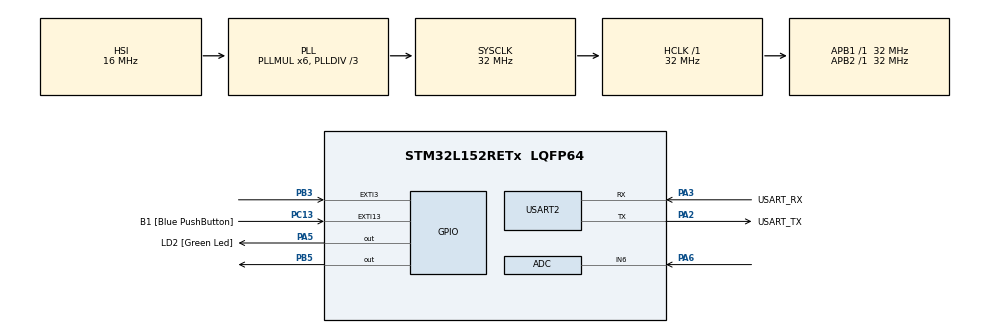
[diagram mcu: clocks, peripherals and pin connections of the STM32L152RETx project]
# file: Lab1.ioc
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ADC.Channel-0\#ChannelRegularConversion=ADC_CHANNEL_6
ADC.NbrOfConversionFlag=1
ADC.Rank-0\#ChannelRegularConversion=1
ADC.SamplingTime-0\#ChannelRegularConversion=ADC_SAMPLETIME_4CYCLES
Mcu.Family=STM32L1
Mcu.Name=STM32L152RETx
Mcu.Package=LQFP64
NVIC.PriorityGroup=NVIC_PRIORITYGROUP_0
PA13.GPIO_Label=TMS
PA13.Mode=Serial_Wire
PA13.Signal=SYS_JTMS-SWDIO
PA14.GPIO_Label=TCK
PA14.Mode=Serial_Wire
PA14.Signal=SYS_JTCK-SWCLK
PA2.GPIO_Label=USART_TX
PA2.Mode=Asynchronous
PA2.Signal=USART2_TX
PA3.GPIO_Label=USART_RX
PA3.Mode=Asynchronous
PA3.Signal=USART2_RX
PA5.GPIO_Label=LD2 [Green Led]
PA5.Signal=GPIO_Output
PA6.Mode=IN6
PA6.Signal=ADC_IN6
PB3.Signal=GPXTI3
PB5.Signal=GPIO_Output
PC13-WKUP2.GPIO_Label=B1 [Blue PushButton]
PC13-WKUP2.Signal=GPXTI13
PC14-OSC32_IN.Mode=LSE-External-Oscillator
PC14-OSC32_IN.Signal=RCC_OSC32_IN
PC15-OSC32_OUT.Mode=LSE-External-Oscillator
PC15-OSC32_OUT.Signal=RCC_OSC32_OUT
PH0-OSC_IN.Mode=HSE-External-Clock-Source
PH0-OSC_IN.Signal=RCC_OSC_IN
PH1-OSC_OUT.Signal=RCC_OSC_OUT
ProjectManager.HeapSize=0x200
ProjectManager.StackSize=0x400
ProjectManager.TargetToolchain=STM32CubeIDE
RCC.48MHZClocksFreq_Value=48000000
RCC.AHBFreq_Value=32000000
RCC.APB1Freq_Value=32000000
RCC.APB1TimFreq_Value=32000000
RCC.APB2Freq_Value=32000000
RCC.APB2TimFreq_Value=32000000
RCC.HCLKFreq_Value=32000000
RCC.HSE_VALUE=8000000
RCC.HSI_VALUE=16000000
RCC.MSI_VALUE=2097000
RCC.PLLDIV=RCC_PLL_DIV3
RCC.PLLMUL=RCC_PLL_MUL6
RCC.RTCClockSelectionVirtual=RCC_RTCCLKSOURCE_LSE
RCC.SYSCLKFreq_VALUE=32000000
RCC.SYSCLKSource=RCC_SYSCLKSOURCE_PLLCLK
RCC.USBOutput=48000000
RCC.VCOOutputFreq_Value=96000000
USART2.VirtualMode=VM_ASYNC
board=NUCLEO-L152RE

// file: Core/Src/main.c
/* USER CODE BEGIN Header */
/**
  ******************************************************************************
  * @file           : main.c
  * @brief          : Main program body
  ******************************************************************************
  * @attention
  *
  * Copyright (c) 2026 STMicroelectronics.
  * All rights reserved.
  *
  * This software is licensed under terms that can be found in the LICENSE file
  * in the root directory of this software component.
  * If no LICENSE file comes with this software, it is provided AS-IS.
  *
  ******************************************************************************
  */
/* USER CODE END Header */
#include "main.h"

/* USER CODE BEGIN Includes */
extern UART_HandleTypeDef huart2;

int _write(int file, char *ptr, int len) {
	int i=0;
	for(i=0; i<len; i++)
	HAL_UART_Transmit(&huart2,(uint8_t *)(ptr++),1,1000);
	return len;
}
void waiting(unsigned int delay) {
	unsigned int i;
	for (i=0; i<delay; i++);
}
/* USER CODE END Includes */

ADC_HandleTypeDef hadc;

UART_HandleTypeDef huart2;

/* USER CODE BEGIN PV */
unsigned char state = 0;
unsigned char medicion_init = 0;
unsigned char medicion_end = 1;
uint32_t value_adc = 0;
int angle = 0;
/* USER CODE END PV */

void SystemClock_Config(void);
static void MX_GPIO_Init(void);
static void MX_ADC_Init(void);
static void MX_USART2_UART_Init(void);

/* USER CODE BEGIN 0 */
void EXTI15_10_IRQHandler(void){
	if(EXTI->PR & (1 << 13)){
		EXTI->PR = (0x01 << 13);
		state = state + 1;
		if (state >1) state = 0;
		if (medicion_end == 0) printf("El cambio se realizara al terminar la medicion \r\n");
	}
}

void EXTI4_IRQHandler(void){
	// no need to verify EXTI PR as it only triggers this function with EXTI4
	EXTI->PR = (0x01 << 4);
	medicion_init = 1;
	medicion_end = 0;

}
/* USER CODE END 0 */

int main(void)
{

  /* USER CODE BEGIN 1 */
	unsigned char prev_state = 0;
  /* USER CODE END 1 */

  /* MCU Configuration--------------------------------------------------------*/

  /* Reset of all peripherals, Initializes the Flash interface and the Systick. */
  HAL_Init();

  /* Configure the system clock */
  SystemClock_Config();

  /* Initialize all configured peripherals */
  MX_GPIO_Init();
  MX_ADC_Init();
  MX_USART2_UART_Init();
  /* USER CODE BEGIN 2 */
  /*INPUTS: */
  /*PB4 configuration EXTI mode, moder (00)*/
  GPIOB ->MODER &= ~(1 << (4*2 + 1));
  GPIOB ->MODER &= ~(1 << (4*2));
  GPIOB ->PUPDR &= ~(3 << 8); // cleaning any previous configuration
  GPIOB ->PUPDR |= (2 << 8); // Setting button on pull down (10)

  SYSCFG ->EXTICR[1] &= ~(0xF << 0);	//Cleaning any new previous at SYSCFG
  SYSCFG->EXTICR[1] |= (0x01 << 0);		// Enabling EXTI4 for PB4 with 0001
  EXTI ->FTSR &= ~(0x01 << 4);			// Disabling falling edge
  EXTI ->RTSR |= (0x01 << 4);			// Enabling rising edge
  EXTI ->IMR |= (0x01 << 4); 			// Enable EXTI 4
  NVIC ->ISER[0] |= (1 << 10); 	// Enable EXTI4 NVIC

  /*PC13 configuration EXTI mode, moder(00)*/
  GPIOC ->MODER &= ~(1 << (13*2 + 1));
  GPIOC ->MODER &= ~(1 << (13*2));

  SYSCFG ->EXTICR[3] &= ~(0xF << 4);	//Cleaning any new previous at SYSCFG
  SYSCFG->EXTICR[3] |= (0x02 << 4);		// Enabling EXTI13 for PC13 with 0010
  EXTI ->FTSR |= (0x01 << 13);			// Enable falling edge
  EXTI ->RTSR &= ~(0x01 << 13);			// Disable rising edge
  EXTI ->IMR |= (0x01 << 13); 			// Enable EXTI 13
  NVIC ->ISER[1] |= (1 << (40-32)); 	// Enable EXTI15_10 NVIC

  /*OUTPUTS: */
  /*PA5 configuration in output mode, moder(01)  */
  GPIOA ->MODER &= ~(1 << (5*2 + 1));
  GPIOA ->MODER |= (1 << (5*2));

  /*PB5 configuration of the external led, moder(01)*/
  GPIOB ->MODER &= ~(1 << (5*2 + 1));
  GPIOB ->MODER |= (1 << (5*2));

  /* USER CODE END 2 */

  /* Infinite loop */
  /* USER CODE BEGIN WHILE */
  while (1)
  {
	  if ((state != prev_state) && (medicion_end == 1)){
		  prev_state = state;
		  switch(state){
		  case 0: //Manual Mode led off
			  printf("Modo manual \r\n");
			  GPIOA->BSRR = (1<<5)<<16;
			  break;

		  default: //Automatic Mode led onn
			  printf("Modo automatico \r\n");
			  GPIOA->BSRR = (1<<5);
		  }
	  }
	  if (state == 0){
		  /*Reading ADC*/
		  if(medicion_init == 1){
			  medicion_init = 0;
			  //reads the potenciometer (ADC)
			  printf("Modo Manual -> Angulo del servomotor: \r\n");
			  GPIOB->BSRR = (1<<5);
			  waiting(4000000); //0.5s this must be changed after by a timer
			  GPIOB->BSRR = (1<<5)<<16;
			  medicion_end = 1;
		  }
	  }else{
		  if(medicion_init == 1){
			  medicion_init = 0;
			  for(int i = 0; i<5; i++){
				  angle = -90 + i*45;
				  printf("Modo automatico -> Angulo del servomotor: %d\r\n", angle);
				  for(int j = 0; j<2;j++){
				  	  GPIOB->BSRR = (1<<5);
				  	  waiting(4000000);//0.5s this must be changed after by a timer
				  	  GPIOB->BSRR = (1<<5)<<16;
				  	  waiting(4000000);//0.5s this must be changed after by a timer
				  }
			  }
			  printf("Volviendo a posicion inicial -> Angulo del servomotor: 0 \r\n");
		  }
	  }
    /* USER CODE END WHILE */

  }
}

void SystemClock_Config(void)
{
  RCC_OscInitTypeDef RCC_OscInitStruct = {0};
  RCC_ClkInitTypeDef RCC_ClkInitStruct = {0};

  /** Configure the main internal regulator output voltage
  */
  __HAL_PWR_VOLTAGESCALING_CONFIG(PWR_REGULATOR_VOLTAGE_SCALE1);

  /** Initializes the RCC Oscillators according to the specified parameters
  * in the RCC_OscInitTypeDef structure.
  */
  RCC_OscInitStruct.OscillatorType = RCC_OSCILLATORTYPE_HSI;
  RCC_OscInitStruct.HSIState = RCC_HSI_ON;
  RCC_OscInitStruct.HSICalibrationValue = RCC_HSICALIBRATION_DEFAULT;
  RCC_OscInitStruct.PLL.PLLState = RCC_PLL_ON;
  RCC_OscInitStruct.PLL.PLLSource = RCC_PLLSOURCE_HSI;
  RCC_OscInitStruct.PLL.PLLMUL = RCC_PLL_MUL6;
  RCC_OscInitStruct.PLL.PLLDIV = RCC_PLL_DIV3;
  if (HAL_RCC_OscConfig(&RCC_OscInitStruct) != HAL_OK)
  {
    Error_Handler();
  }

  /** Initializes the CPU, AHB and APB buses clocks
  */
  RCC_ClkInitStruct.ClockType = RCC_CLOCKTYPE_HCLK|RCC_CLOCKTYPE_SYSCLK
                              |RCC_CLOCKTYPE_PCLK1|RCC_CLOCKTYPE_PCLK2;
  RCC_ClkInitStruct.SYSCLKSource = RCC_SYSCLKSOURCE_PLLCLK;
  RCC_ClkInitStruct.AHBCLKDivider = RCC_SYSCLK_DIV1;
  RCC_ClkInitStruct.APB1CLKDivider = RCC_HCLK_DIV1;
  RCC_ClkInitStruct.APB2CLKDivider = RCC_HCLK_DIV1;

  if (HAL_RCC_ClockConfig(&RCC_ClkInitStruct, FLASH_LATENCY_1) != HAL_OK)
  {
    Error_Handler();
  }
}

static void MX_ADC_Init(void)
{

  ADC_ChannelConfTypeDef sConfig = {0};

  /** Configure the global features of the ADC (Clock, Resolution, Data Alignment and number of conversion)
  */
  hadc.Instance = ADC1;
  hadc.Init.ClockPrescaler = ADC_CLOCK_ASYNC_DIV1;
  hadc.Init.Resolution = ADC_RESOLUTION_12B;
  hadc.Init.DataAlign = ADC_DATAALIGN_RIGHT;
  hadc.Init.ScanConvMode = ADC_SCAN_DISABLE;
  hadc.Init.EOCSelection = ADC_EOC_SEQ_CONV;
  hadc.Init.LowPowerAutoWait = ADC_AUTOWAIT_DISABLE;
  hadc.Init.LowPowerAutoPowerOff = ADC_AUTOPOWEROFF_DISABLE;
  hadc.Init.ChannelsBank = ADC_CHANNELS_BANK_A;
  hadc.Init.ContinuousConvMode = DISABLE;
  hadc.Init.NbrOfConversion = 1;
  hadc.Init.DiscontinuousConvMode = DISABLE;
  hadc.Init.ExternalTrigConv = ADC_SOFTWARE_START;
  hadc.Init.ExternalTrigConvEdge = ADC_EXTERNALTRIGCONVEDGE_NONE;
  hadc.Init.DMAContinuousRequests = DISABLE;
  if (HAL_ADC_Init(&hadc) != HAL_OK)
  {
    Error_Handler();
  }

  /** Configure for the selected ADC regular channel its corresponding rank in the sequencer and its sample time.
  */
  sConfig.Channel = ADC_CHANNEL_1;
  sConfig.Rank = ADC_REGULAR_RANK_1;
  sConfig.SamplingTime = ADC_SAMPLETIME_4CYCLES;
  if (HAL_ADC_ConfigChannel(&hadc, &sConfig) != HAL_OK)
  {
    Error_Handler();
  }

}

static void MX_USART2_UART_Init(void)
{

  huart2.Instance = USART2;
  huart2.Init.BaudRate = 115200;
  huart2.Init.WordLength = UART_WORDLENGTH_8B;
  huart2.Init.StopBits = UART_STOPBITS_1;
  huart2.Init.Parity = UART_PARITY_NONE;
  huart2.Init.Mode = UART_MODE_TX_RX;
  huart2.Init.HwFlowCtl = UART_HWCONTROL_NONE;
  huart2.Init.OverSampling = UART_OVERSAMPLING_16;
  if (HAL_UART_Init(&huart2) != HAL_OK)
  {
    Error_Handler();
  }

}

static void MX_GPIO_Init(void)
{
  GPIO_InitTypeDef GPIO_InitStruct = {0};

  /* GPIO Ports Clock Enable */
  __HAL_RCC_GPIOC_CLK_ENABLE();
  __HAL_RCC_GPIOH_CLK_ENABLE();
  __HAL_RCC_GPIOA_CLK_ENABLE();
  __HAL_RCC_GPIOB_CLK_ENABLE();

  /*Configure GPIO pin Output Level */
  HAL_GPIO_WritePin(LD2_GPIO_Port, LD2_Pin, GPIO_PIN_RESET);

  /*Configure GPIO pin Output Level */
  HAL_GPIO_WritePin(GPIOB, GPIO_PIN_5, GPIO_PIN_RESET);

  /*Configure GPIO pin : B1_Pin */
  GPIO_InitStruct.Pin = B1_Pin;
  GPIO_InitStruct.Mode = GPIO_MODE_IT_RISING;
  GPIO_InitStruct.Pull = GPIO_NOPULL;
  HAL_GPIO_Init(B1_GPIO_Port, &GPIO_InitStruct);

  /*Configure GPIO pin : LD2_Pin */
  GPIO_InitStruct.Pin = LD2_Pin;
  GPIO_InitStruct.Mode = GPIO_MODE_OUTPUT_PP;
  GPIO_InitStruct.Pull = GPIO_NOPULL;
  GPIO_InitStruct.Speed = GPIO_SPEED_FREQ_LOW;
  HAL_GPIO_Init(LD2_GPIO_Port, &GPIO_InitStruct);

  /*Configure GPIO pin : PB4 */
  GPIO_InitStruct.Pin = GPIO_PIN_4;
  GPIO_InitStruct.Mode = GPIO_MODE_IT_RISING;
  GPIO_InitStruct.Pull = GPIO_NOPULL;
  HAL_GPIO_Init(GPIOB, &GPIO_InitStruct);

  /*Configure GPIO pin : PB5 */
  GPIO_InitStruct.Pin = GPIO_PIN_5;
  GPIO_InitStruct.Mode = GPIO_MODE_OUTPUT_PP;
  GPIO_InitStruct.Pull = GPIO_NOPULL;
  GPIO_InitStruct.Speed = GPIO_SPEED_FREQ_LOW;
  HAL_GPIO_Init(GPIOB, &GPIO_InitStruct);

}

void Error_Handler(void)
{
  __disable_irq();
  while (1)
  {
  }
}
